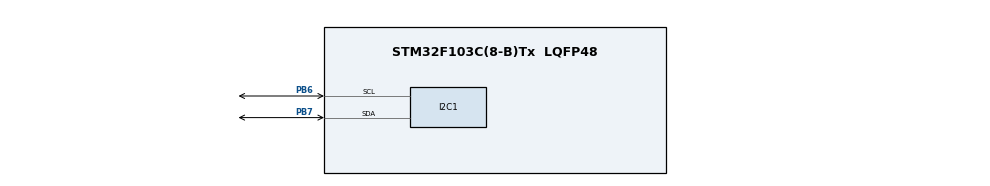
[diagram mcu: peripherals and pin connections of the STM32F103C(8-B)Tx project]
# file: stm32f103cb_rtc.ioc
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Mcu.Family=STM32F1
Mcu.Name=STM32F103C(8-B)Tx
Mcu.Package=LQFP48
NVIC.PriorityGroup=NVIC_PRIORITYGROUP_4
PA13.Mode=Serial_Wire
PA13.Signal=SYS_JTMS-SWDIO
PA14.Mode=Serial_Wire
PA14.Signal=SYS_JTCK-SWCLK
PB6.Mode=I2C
PB6.Signal=I2C1_SCL
PB7.Mode=I2C
PB7.Signal=I2C1_SDA
PD0-OSC_IN.Mode=HSE-External-Clock-Source
PD0-OSC_IN.Signal=RCC_OSC_IN
PD1-OSC_OUT.Mode=HSE-External-Clock-Source
PD1-OSC_OUT.Signal=RCC_OSC_OUT
ProjectManager.HeapSize=0x200
ProjectManager.StackSize=0x400
ProjectManager.TargetToolchain=STM32CubeIDE
RCC.APB1Freq_Value=8000000
RCC.APB2Freq_Value=8000000
board=custom

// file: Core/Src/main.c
/* USER CODE BEGIN Header */
/**
  ******************************************************************************
  * @file           : main.c
  * @brief          : Main program body
  ******************************************************************************
  * @attention
  *
  * Copyright (c) 2025 STMicroelectronics.
  * All rights reserved.
  *
  * This software is licensed under terms that can be found in the LICENSE file
  * in the root directory of this software component.
  * If no LICENSE file comes with this software, it is provided AS-IS.
  *
  ******************************************************************************
  */
/* USER CODE END Header */
#include "main.h"

/* USER CODE BEGIN Includes */

#include "stdio.h"

/* USER CODE END Includes */

I2C_HandleTypeDef hi2c1;

void SystemClock_Config(void);
static void MX_GPIO_Init(void);
static void MX_I2C1_Init(void);

/* USER CODE BEGIN 0 */

#define DS3231_ADDRESS 0x68

// Convert normal decimal numbers to binary coded decimal
uint8_t decToBcd(int val)
{
    return (uint8_t)((val / 10 * 16) + (val % 10));
}

// Convert binary coded decimal to normal decimal numbers
int bcdToDec(uint8_t val)
{
    return (int)((val / 16 * 10) + (val % 16));
}

// Declare individual variables for time and date
uint8_t seconds, minutes, hour, dayofweek, dayofmonth, month, year;

// Function to set time
void Set_Time(uint8_t sec, uint8_t min, uint8_t hr, uint8_t dow, uint8_t dom, uint8_t mon, uint8_t yr)
{
    uint8_t set_time[7];
    set_time[0] = decToBcd(sec);   // Seconds
    set_time[1] = decToBcd(min);   // Minutes
    set_time[2] = decToBcd(hr);    // Hours
    set_time[3] = decToBcd(dow);   // Day of week
    set_time[4] = decToBcd(dom);   // Day of month
    set_time[5] = decToBcd(mon);   // Month
    set_time[6] = decToBcd(yr);    // Year

    HAL_I2C_Mem_Write(&hi2c1, DS3231_ADDRESS << 1, 0x00, 1, set_time, 7, 1000);
}

// Function to get time
void Get_Time(void)
{
    uint8_t get_time[7];
    HAL_I2C_Mem_Read(&hi2c1, DS3231_ADDRESS << 1, 0x00, 1, get_time, 7, 1000);

    // Convert BCD values to decimal and store in individual variables
    seconds = bcdToDec(get_time[0]);
    minutes = bcdToDec(get_time[1]);
    hour = bcdToDec(get_time[2]);
    dayofweek = bcdToDec(get_time[3]);
    dayofmonth = bcdToDec(get_time[4]);
    month = bcdToDec(get_time[5]);
    year = bcdToDec(get_time[6]);
}

/* USER CODE END 0 */

int main(void)
{

  /* MCU Configuration--------------------------------------------------------*/

  /* Reset of all peripherals, Initializes the Flash interface and the Systick. */
  HAL_Init();

  /* Configure the system clock */
  SystemClock_Config();

  /* Initialize all configured peripherals */
  MX_GPIO_Init();
  MX_I2C1_Init();
  /* USER CODE BEGIN 2 */
//  Set_Time(00, 54, 7, 1, 19, 5, 25);
  /* USER CODE END 2 */

  /* Infinite loop */
  while (1)
  {

    /* USER CODE BEGIN 3 */
    Get_Time();
    HAL_Delay(500);
  }
  /* USER CODE END 3 */
}

void SystemClock_Config(void)
{
  RCC_OscInitTypeDef RCC_OscInitStruct = {0};
  RCC_ClkInitTypeDef RCC_ClkInitStruct = {0};

  /** Initializes the RCC Oscillators according to the specified parameters
  * in the RCC_OscInitTypeDef structure.
  */
  RCC_OscInitStruct.OscillatorType = RCC_OSCILLATORTYPE_HSI;
  RCC_OscInitStruct.HSIState = RCC_HSI_ON;
  RCC_OscInitStruct.HSICalibrationValue = RCC_HSICALIBRATION_DEFAULT;
  RCC_OscInitStruct.PLL.PLLState = RCC_PLL_NONE;
  if (HAL_RCC_OscConfig(&RCC_OscInitStruct) != HAL_OK)
  {
    Error_Handler();
  }

  /** Initializes the CPU, AHB and APB buses clocks
  */
  RCC_ClkInitStruct.ClockType = RCC_CLOCKTYPE_HCLK|RCC_CLOCKTYPE_SYSCLK
                              |RCC_CLOCKTYPE_PCLK1|RCC_CLOCKTYPE_PCLK2;
  RCC_ClkInitStruct.SYSCLKSource = RCC_SYSCLKSOURCE_HSI;
  RCC_ClkInitStruct.AHBCLKDivider = RCC_SYSCLK_DIV1;
  RCC_ClkInitStruct.APB1CLKDivider = RCC_HCLK_DIV1;
  RCC_ClkInitStruct.APB2CLKDivider = RCC_HCLK_DIV1;

  if (HAL_RCC_ClockConfig(&RCC_ClkInitStruct, FLASH_LATENCY_0) != HAL_OK)
  {
    Error_Handler();
  }
}

static void MX_I2C1_Init(void)
{

  hi2c1.Instance = I2C1;
  hi2c1.Init.ClockSpeed = 100000;
  hi2c1.Init.DutyCycle = I2C_DUTYCYCLE_2;
  hi2c1.Init.OwnAddress1 = 0;
  hi2c1.Init.AddressingMode = I2C_ADDRESSINGMODE_7BIT;
  hi2c1.Init.DualAddressMode = I2C_DUALADDRESS_DISABLE;
  hi2c1.Init.OwnAddress2 = 0;
  hi2c1.Init.GeneralCallMode = I2C_GENERALCALL_DISABLE;
  hi2c1.Init.NoStretchMode = I2C_NOSTRETCH_DISABLE;
  if (HAL_I2C_Init(&hi2c1) != HAL_OK)
  {
    Error_Handler();
  }

}

static void MX_GPIO_Init(void)
{

  /* GPIO Ports Clock Enable */
  __HAL_RCC_GPIOD_CLK_ENABLE();
  __HAL_RCC_GPIOA_CLK_ENABLE();
  __HAL_RCC_GPIOB_CLK_ENABLE();

}

void Error_Handler(void)
{
  __disable_irq();
  while (1)
  {
  }
}
